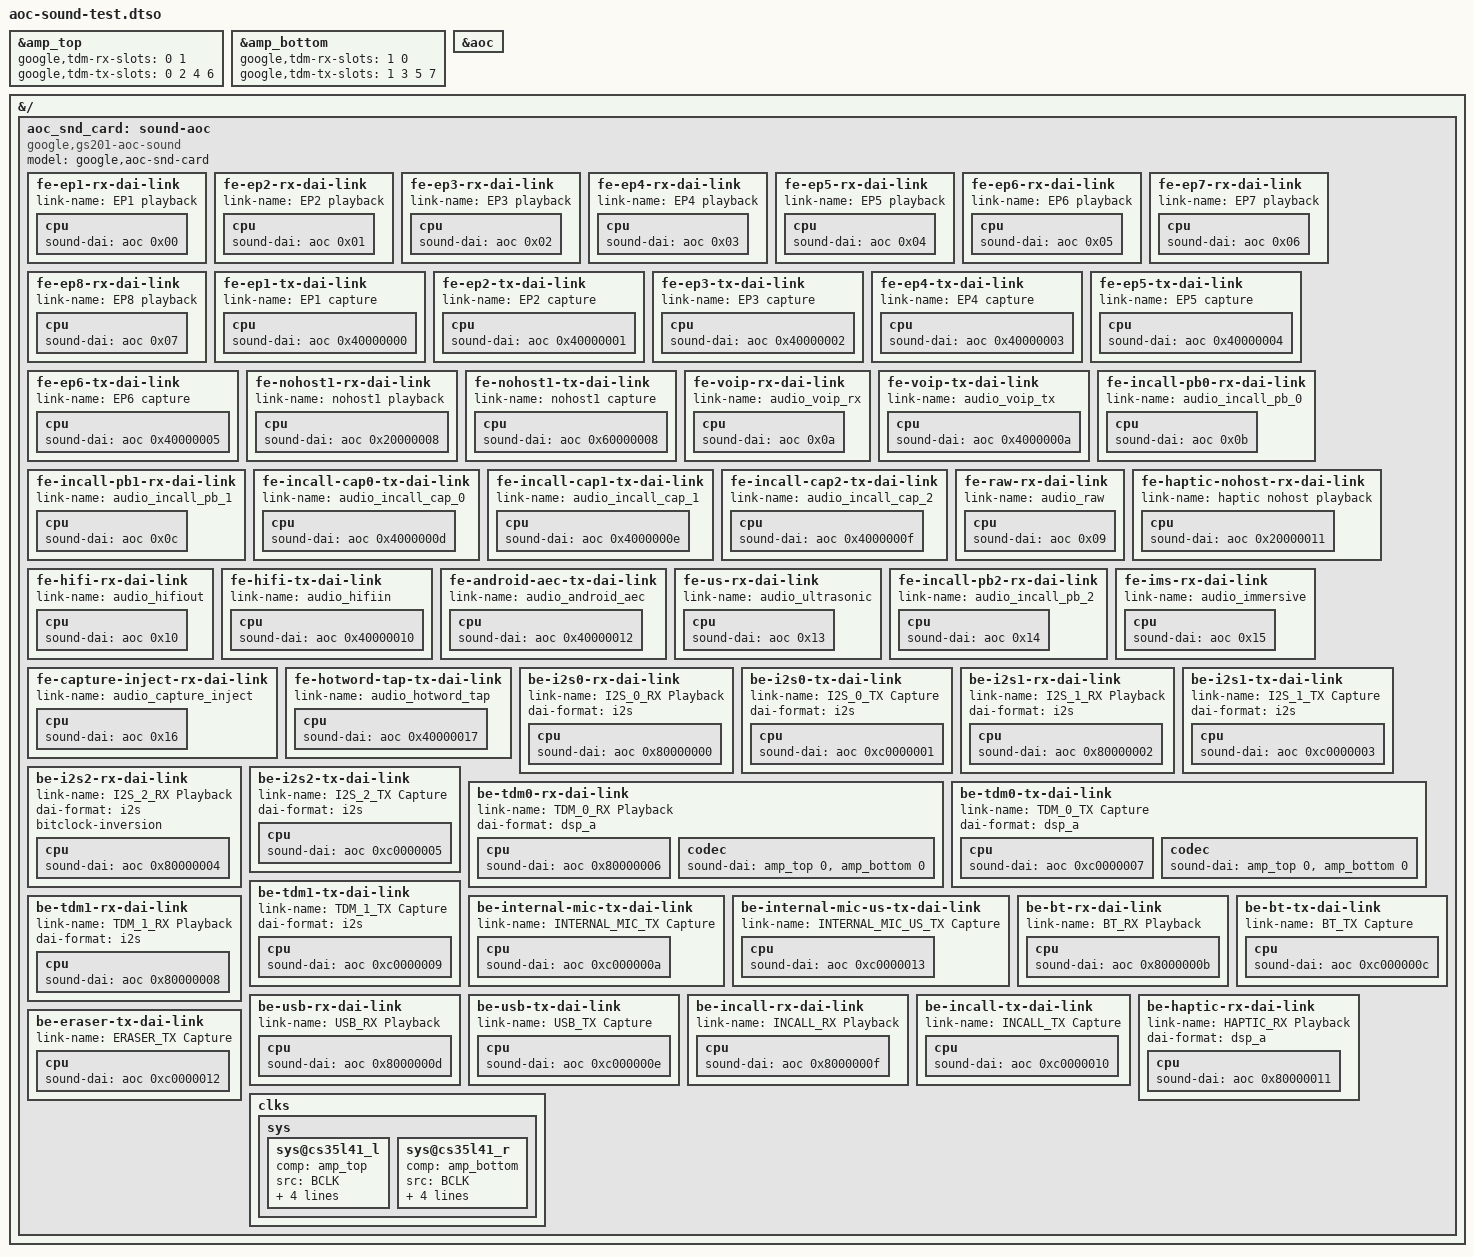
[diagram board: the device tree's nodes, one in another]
// SPDX-License-Identifier: MIT
/*
 * Bring-up only (AOC-PLAN.md, stage C7): the AoC sound card in the form of
 * linux-omamobile's google,gs201-aoc-sound binding (#193): the AoC node is
 * the DAI provider, each link names its AoC DAI by the link id of the stock
 * tree, its stream name as link-name and a back end's wire format, with the
 * speaker amplifiers as the TDM 0 codecs (amp_top and amp_bottom from the
 * cheetah device tree) and the haptics codec links left without a codec. The
 * card driver derives the rest from the cell. Apply with audio-amps-test (SPI7
 * and the amplifiers) and aoc-core-test.
 *
 * TDM 0 slots (AUDIO-PLAN.md 1.1): the top amplifier plays slot 0, the
 * bottom one slot 1. Their VMON/IMON feedback (ASP TX1-TX4) goes out
 * interleaved, as stock's mixer_paths.xml sets it (top 0, 2, 4, 6; bottom
 * 1, 3, 5, 7), so the two never drive the shared SDOUT line in the same
 * slot. Without it both used the reset slots 0-3 (AOC-PLAN C9d-6).
 *
 * The card driver sorts the DAI links into the stock order by their ids, so
 * the PCM numbers (which are the AoC entry points) do not depend on the order
 * in which the overlay apply leaves these nodes.
 */
/dts-v1/;
/plugin/;

&amp_top {
	google,tdm-rx-slots = <0 1>;
	google,tdm-tx-slots = <0 2 4 6>;
};

&amp_bottom {
	google,tdm-rx-slots = <1 0>;
	google,tdm-tx-slots = <1 3 5 7>;
};

&aoc {
	#sound-dai-cells = <1>;
};

&{/} {
		aoc_snd_card: sound-aoc {
			compatible = "google,gs201-aoc-sound";
			model = "google,aoc-snd-card";

			fe-ep1-rx-dai-link {
				link-name = "EP1 playback";

				cpu {
					sound-dai = <&aoc 0x00>;
				};
			};

			fe-ep2-rx-dai-link {
				link-name = "EP2 playback";

				cpu {
					sound-dai = <&aoc 0x01>;
				};
			};

			fe-ep3-rx-dai-link {
				link-name = "EP3 playback";

				cpu {
					sound-dai = <&aoc 0x02>;
				};
			};

			fe-ep4-rx-dai-link {
				link-name = "EP4 playback";

				cpu {
					sound-dai = <&aoc 0x03>;
				};
			};

			fe-ep5-rx-dai-link {
				link-name = "EP5 playback";

				cpu {
					sound-dai = <&aoc 0x04>;
				};
			};

			fe-ep6-rx-dai-link {
				link-name = "EP6 playback";

				cpu {
					sound-dai = <&aoc 0x05>;
				};
			};

			fe-ep7-rx-dai-link {
				link-name = "EP7 playback";

				cpu {
					sound-dai = <&aoc 0x06>;
				};
			};

			fe-ep8-rx-dai-link {
				link-name = "EP8 playback";

				cpu {
					sound-dai = <&aoc 0x07>;
				};
			};

			fe-ep1-tx-dai-link {
				link-name = "EP1 capture";

				cpu {
					sound-dai = <&aoc 0x40000000>;
				};
			};

			fe-ep2-tx-dai-link {
				link-name = "EP2 capture";

				cpu {
					sound-dai = <&aoc 0x40000001>;
				};
			};

			fe-ep3-tx-dai-link {
				link-name = "EP3 capture";

				cpu {
					sound-dai = <&aoc 0x40000002>;
				};
			};

			fe-ep4-tx-dai-link {
				link-name = "EP4 capture";

				cpu {
					sound-dai = <&aoc 0x40000003>;
				};
			};

			fe-ep5-tx-dai-link {
				link-name = "EP5 capture";

				cpu {
					sound-dai = <&aoc 0x40000004>;
				};
			};

			fe-ep6-tx-dai-link {
				link-name = "EP6 capture";

				cpu {
					sound-dai = <&aoc 0x40000005>;
				};
			};

			fe-nohost1-rx-dai-link {
				link-name = "nohost1 playback";

				cpu {
					sound-dai = <&aoc 0x20000008>;
				};
			};

			fe-nohost1-tx-dai-link {
				link-name = "nohost1 capture";

				cpu {
					sound-dai = <&aoc 0x60000008>;
				};
			};

			fe-voip-rx-dai-link {
				link-name = "audio_voip_rx";

				cpu {
					sound-dai = <&aoc 0x0a>;
				};
			};

			fe-voip-tx-dai-link {
				link-name = "audio_voip_tx";

				cpu {
					sound-dai = <&aoc 0x4000000a>;
				};
			};

			fe-incall-pb0-rx-dai-link {
				link-name = "audio_incall_pb_0";

				cpu {
					sound-dai = <&aoc 0x0b>;
				};
			};

			fe-incall-pb1-rx-dai-link {
				link-name = "audio_incall_pb_1";

				cpu {
					sound-dai = <&aoc 0x0c>;
				};
			};

			fe-incall-cap0-tx-dai-link {
				link-name = "audio_incall_cap_0";

				cpu {
					sound-dai = <&aoc 0x4000000d>;
				};
			};

			fe-incall-cap1-tx-dai-link {
				link-name = "audio_incall_cap_1";

				cpu {
					sound-dai = <&aoc 0x4000000e>;
				};
			};

			fe-incall-cap2-tx-dai-link {
				link-name = "audio_incall_cap_2";

				cpu {
					sound-dai = <&aoc 0x4000000f>;
				};
			};

			fe-raw-rx-dai-link {
				link-name = "audio_raw";

				cpu {
					sound-dai = <&aoc 0x09>;
				};
			};

			fe-haptic-nohost-rx-dai-link {
				link-name = "haptic nohost playback";

				cpu {
					sound-dai = <&aoc 0x20000011>;
				};
			};

			fe-hifi-rx-dai-link {
				link-name = "audio_hifiout";

				cpu {
					sound-dai = <&aoc 0x10>;
				};
			};

			fe-hifi-tx-dai-link {
				link-name = "audio_hifiin";

				cpu {
					sound-dai = <&aoc 0x40000010>;
				};
			};

			fe-android-aec-tx-dai-link {
				link-name = "audio_android_aec";

				cpu {
					sound-dai = <&aoc 0x40000012>;
				};
			};

			fe-us-rx-dai-link {
				link-name = "audio_ultrasonic";

				cpu {
					sound-dai = <&aoc 0x13>;
				};
			};

			fe-incall-pb2-rx-dai-link {
				link-name = "audio_incall_pb_2";

				cpu {
					sound-dai = <&aoc 0x14>;
				};
			};

			fe-ims-rx-dai-link {
				link-name = "audio_immersive";

				cpu {
					sound-dai = <&aoc 0x15>;
				};
			};

			fe-capture-inject-rx-dai-link {
				link-name = "audio_capture_inject";

				cpu {
					sound-dai = <&aoc 0x16>;
				};
			};

			fe-hotword-tap-tx-dai-link {
				link-name = "audio_hotword_tap";

				cpu {
					sound-dai = <&aoc 0x40000017>;
				};
			};

			be-i2s0-rx-dai-link {
				link-name = "I2S_0_RX Playback";
				dai-format = "i2s";

				cpu {
					sound-dai = <&aoc 0x80000000>;
				};
			};

			be-i2s0-tx-dai-link {
				link-name = "I2S_0_TX Capture";
				dai-format = "i2s";

				cpu {
					sound-dai = <&aoc 0xc0000001>;
				};
			};

			be-i2s1-rx-dai-link {
				link-name = "I2S_1_RX Playback";
				dai-format = "i2s";

				cpu {
					sound-dai = <&aoc 0x80000002>;
				};
			};

			be-i2s1-tx-dai-link {
				link-name = "I2S_1_TX Capture";
				dai-format = "i2s";

				cpu {
					sound-dai = <&aoc 0xc0000003>;
				};
			};

			be-i2s2-rx-dai-link {
				link-name = "I2S_2_RX Playback";
				dai-format = "i2s";
				bitclock-inversion;

				cpu {
					sound-dai = <&aoc 0x80000004>;
				};
			};

			be-i2s2-tx-dai-link {
				link-name = "I2S_2_TX Capture";
				dai-format = "i2s";

				cpu {
					sound-dai = <&aoc 0xc0000005>;
				};
			};

			be-tdm0-rx-dai-link {
				link-name = "TDM_0_RX Playback";
				dai-format = "dsp_a";

				cpu {
					sound-dai = <&aoc 0x80000006>;
				};

				codec {
					sound-dai = <&amp_top 0>, <&amp_bottom 0>;
				};
			};

			be-tdm0-tx-dai-link {
				link-name = "TDM_0_TX Capture";
				dai-format = "dsp_a";

				cpu {
					sound-dai = <&aoc 0xc0000007>;
				};

				codec {
					sound-dai = <&amp_top 0>, <&amp_bottom 0>;
				};
			};

			be-tdm1-rx-dai-link {
				link-name = "TDM_1_RX Playback";
				dai-format = "i2s";

				cpu {
					sound-dai = <&aoc 0x80000008>;
				};
			};

			be-tdm1-tx-dai-link {
				link-name = "TDM_1_TX Capture";
				dai-format = "i2s";

				cpu {
					sound-dai = <&aoc 0xc0000009>;
				};
			};

			be-internal-mic-tx-dai-link {
				link-name = "INTERNAL_MIC_TX Capture";

				cpu {
					sound-dai = <&aoc 0xc000000a>;
				};
			};

			be-internal-mic-us-tx-dai-link {
				link-name = "INTERNAL_MIC_US_TX Capture";

				cpu {
					sound-dai = <&aoc 0xc0000013>;
				};
			};

			be-bt-rx-dai-link {
				link-name = "BT_RX Playback";

				cpu {
					sound-dai = <&aoc 0x8000000b>;
				};
			};

			be-bt-tx-dai-link {
				link-name = "BT_TX Capture";

				cpu {
					sound-dai = <&aoc 0xc000000c>;
				};
			};

			be-usb-rx-dai-link {
				link-name = "USB_RX Playback";

				cpu {
					sound-dai = <&aoc 0x8000000d>;
				};
			};

			be-usb-tx-dai-link {
				link-name = "USB_TX Capture";

				cpu {
					sound-dai = <&aoc 0xc000000e>;
				};
			};

			be-incall-rx-dai-link {
				link-name = "INCALL_RX Playback";

				cpu {
					sound-dai = <&aoc 0x8000000f>;
				};
			};

			be-incall-tx-dai-link {
				link-name = "INCALL_TX Capture";

				cpu {
					sound-dai = <&aoc 0xc0000010>;
				};
			};

			be-haptic-rx-dai-link {
				link-name = "HAPTIC_RX Playback";
				dai-format = "dsp_a";

				cpu {
					sound-dai = <&aoc 0x80000011>;
				};
			};

			be-eraser-tx-dai-link {
				link-name = "ERASER_TX Capture";

				cpu {
					sound-dai = <&aoc 0xc0000012>;
				};
			};

			clks {

				sys {


					sys@cs35l41_l {
						comp = <&amp_top>;
						src = "BCLK";
						id = <0x00>;
						srcid = <0x00>;
						in_mul = <0x01>;
						out_mul = <0x01>;
					};

					sys@cs35l41_r {
						comp = <&amp_bottom>;
						src = "BCLK";
						id = <0x00>;
						srcid = <0x00>;
						in_mul = <0x01>;
						out_mul = <0x01>;
					};
				};
			};
		};
};

